AUTOSAR XML (schema 4-2-2)
package /Components
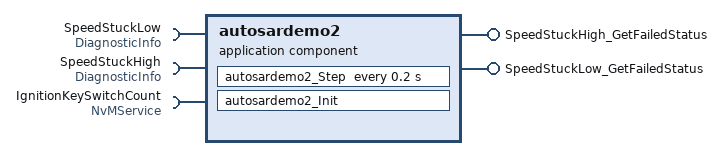
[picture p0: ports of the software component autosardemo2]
  application sw component type autosardemo2
    provide port SpeedStuckHigh_GetFailedStatus: nonqueued-sender-com-spec{data-element=SpeedStuckHigh_GetFailedStatus, init-value=0}, provided-interface=SpeedStuckHigh_GetFailedStatus
    provide port SpeedStuckLow_GetFailedStatus: nonqueued-sender-com-spec{data-element=SpeedStuckLow_GetFailedStatus, init-value=0}, provided-interface=SpeedStuckLow_GetFailedStatus
    require port SpeedStuckLow: required-interface=DiagnosticInfo
    require port SpeedStuckHigh: required-interface=DiagnosticInfo
    require port IgnitionKeySwitchCount: required-interface=NvMService
    behavior autosardemo2_IB: handle-termination-and-restart=NO-SUPPORT
      timing event Event_autosardemo2_Step: start-on-event=autosardemo2_Step, period=0.2
      runnable autosardemo2_Init
      runnable autosardemo2_Step
        data-write-access:
          access OUT_SpeedStuckHigh_GetFailedStatus_SpeedStuckHigh_GetFailedStatus: accessed-variable=SpeedStuckHigh_GetFailedStatus.SpeedStuckHigh_GetFailedStatus
          access OUT_SpeedStuckLow_GetFailedStatus_SpeedStuckLow_GetFailedStatus: accessed-variable=SpeedStuckLow_GetFailedStatus.SpeedStuckLow_GetFailedStatus
        sync call SC_SpeedStuckHigh_GetEventFailed: operation=SpeedStuckHigh.GetEventFailed, timeout=1.0E-06
        sync call SC_SpeedStuckLow_GetEventFailed: operation=SpeedStuckLow.GetEventFailed, timeout=1.0E-06
